# MK24F12 register map
Vendor: Freescale Semiconductor, Inc.; Series: Kinetis_K; File version: 1.6
CPU: CM4 r0p1, little endian, no MPU, FPU, VTOR, 4 interrupt priority bits
Registers are 32-bit, read-write, reset 0x0 unless marked. A register's access mark holds for its fields unless they carry their own. Offsets are from the block's base; [hi:lo] are bit positions; {n}, {i} and the like mark numbered series; 'fields as' and 'values as' point back to an identical list.

## AXBS — Crossbar switch
Base 0x40004000; register names take the prefix AXBS_
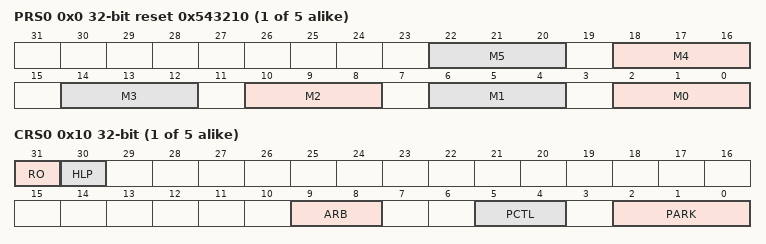
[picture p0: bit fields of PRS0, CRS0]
{0x0+0x100*i} PRS{i} (i=0..4) reset 0x543210 — Priority Registers Slave
  [all] fields
    0=This master has level 1, or highest, priority when accessing the slave port; {v}=This master has level {v+1} priority when accessing the slave port (v=1..6); 7=This master has level 8, or lowest, priority when accessing the slave port
  [4n+2:4n] M{n} (n=0..5) — Master {n} Priority. Sets the arbitration priority for this port on the associated slave port.
{0x10+0x100*i} CRS{i} (i=0..4) — Control Register
  [31] RO — Read Only
    0=The slave port's registers are writeable; 1=The slave port's registers are read-only and cannot be written. Attempted writes have no effect on the registers and result in a bus error response.
  [30] HLP — Halt Low Priority
    0=The low power mode request has the highest priority for arbitration on this slave port; 1=The low power mode request has the lowest initial priority for arbitration on this slave port
  [9:8] ARB — Arbitration Mode
    0=Fixed priority; 1=Round-robin, or rotating, priority
  [5:4] PCTL — Parking Control
    0=When no master makes a request, the arbiter parks the slave port on the master port defined by the PARK field; 1=When no master makes a request, the arbiter parks the slave port on the last master to be in control of the slave port; 2=When no master makes a request, the slave port is not parked on a master and the arbiter drives all outputs to a constant safe state
  [2:0] PARK
    {v}=Park on master port M{v} (v=0..7)
{0x800+0x100*i} MGPCR{i} (i=0..2) — Master General Purpose Control Register
  [2:0] AULB — Arbitrates On Undefined Length Bursts
    0=No arbitration is allowed during an undefined length burst; 1=Arbitration is allowed at any time during an undefined length burst; 2=Arbitration is allowed after four beats of an undefined length burst; 3=Arbitration is allowed after eight beats of an undefined length burst; 4=Arbitration is allowed after 16 beats of an undefined length burst
0xC00 MGPCR4 — Master General Purpose Control Register
  fields as MGPCR0
0xD00 MGPCR5 — Master General Purpose Control Register
  fields as MGPCR0

## FTFE — Flash Memory Interface
Base 0x40020000; register names take the prefix FTFE_
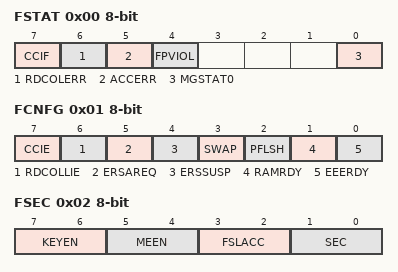
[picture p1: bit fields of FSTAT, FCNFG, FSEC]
0x00 FSTAT 8-bit — Flash Status Register
  [7] CCIF — Command Complete Interrupt Flag
    0=FTFE command in progress; 1=FTFE command has completed
  [6] RDCOLERR — FTFE Read Collision Error Flag
    0=No collision error detected; 1=Collision error detected
  [5] ACCERR — Flash Access Error Flag
    0=No access error detected; 1=Access error detected
  [4] FPVIOL — Flash Protection Violation Flag
    0=No protection violation detected; 1=Protection violation detected
  [0] MGSTAT0 ro — Memory Controller Command Completion Status Flag
0x01 FCNFG 8-bit — Flash Configuration Register
  [7] CCIE — Command Complete Interrupt Enable
    0=Command complete interrupt disabled; 1=Command complete interrupt enabled. An interrupt request is generated whenever the FSTAT[CCIF] flag is set.
  [6] RDCOLLIE — Read Collision Error Interrupt Enable
    0=Read collision error interrupt disabled; 1=Read collision error interrupt enabled. An interrupt request is generated whenever an FTFE read collision error is detected (see the description of FSTAT[RDCOLERR]).
  [5] ERSAREQ ro — Erase All Request
    0=No request or request complete; 1=Request to: run the Erase All Blocks command, verify the erased state, program the security byte in the Flash Configuration Field to the unsecure state, and release MCU security by setting the FSEC[SEC] field to the unsecure state
  [4] ERSSUSP — Erase Suspend
    0=No suspend requested; 1=Suspend the current Erase Flash Sector command execution
  [3] SWAP ro
    0=Program flash 0 block is located at relative address 0x0000; 1=For devices with FlexNVM: Reserved Program flash 1 block is located at relative address 0x0000
  [2] PFLSH ro — FTFE configuration
    1=FTFE configuration supports four program flash blocks
  [1] RAMRDY ro — RAM Ready
    0=Programming acceleration RAM is not available; 1=Programming acceleration RAM is available
  [0] EEERDY ro — During the reset sequence, the EEERDY flag remains clear while CCIF=0 and only sets if the FlexNVM block is partitioned for EEPROM
0x02 FSEC 8-bit ro reset not defined — Flash Security Register
  [7:6] KEYEN — Backdoor Key Security Enable
    0=Backdoor key access disabled; 1=Backdoor key access disabled (preferred KEYEN state to disable backdoor key access); 2=Backdoor key access enabled; 3=Backdoor key access disabled
  [5:4] MEEN — Mass Erase Enable Bits
    0=Mass erase is enabled; 1=Mass erase is enabled; 2=Mass erase is disabled; 3=Mass erase is enabled
  [3:2] FSLACC — Freescale Failure Analysis Access Code
    0=Freescale factory access granted; 1=Freescale factory access denied; 2=Freescale factory access denied; 3=Freescale factory access granted
  [1:0] SEC — Flash Security
    0=MCU security status is secure; 1=MCU security status is secure; 2=MCU security status is unsecure (The standard shipping condition of the FTFE is unsecure.); 3=MCU security status is secure
0x03 FOPT 8-bit ro reset not defined — Flash Option Register
  [7:0] OPT — Nonvolatile Option
0x04 FCCOB{x} (x=3,2,1,0,7,6,5,4,B,A,9,8; step 0x1) 8-bit — Flash Common Command Object Registers
  [7:0] CCOBn — The FCCOB register provides a command code and relevant parameters to the memory controller
0x10 FPROT{x} (x=3,2,1,0; step 0x1) 8-bit reset not defined — Program Flash Protection Registers
  [7:0] PROT — Program Flash Region Protect
    0=Program flash region is protected; 1=Program flash region is not protected

## Notices in the file
Redistribution and use in source and binary forms, with or without modification,
are permitted provided that the following conditions are met:
o Redistributions of source code must retain the above copyright notice, this list
of conditions and the following disclaimer.
o Redistributions in binary form must reproduce the above copyright notice, this
list of conditions and the following disclaimer in the documentation and/or
other materials provided with the distribution.
o Neither the name of Freescale Semiconductor, Inc. nor the names of its
contributors may be used to endorse or promote products derived from this
software without specific prior written permission.
THIS SOFTWARE IS PROVIDED BY THE COPYRIGHT HOLDERS AND CONTRIBUTORS "AS IS" AND
ANY EXPRESS OR IMPLIED WARRANTIES, INCLUDING, BUT NOT LIMITED TO, THE IMPLIED
WARRANTIES OF MERCHANTABILITY AND FITNESS FOR A PARTICULAR PURPOSE ARE
DISCLAIMED. IN NO EVENT SHALL THE COPYRIGHT HOLDER OR CONTRIBUTORS BE LIABLE FOR
ANY DIRECT, INDIRECT, INCIDENTAL, SPECIAL, EXEMPLARY, OR CONSEQUENTIAL DAMAGES
(INCLUDING, BUT NOT LIMITED TO, PROCUREMENT OF SUBSTITUTE GOODS OR SERVICES;
LOSS OF USE, DATA, OR PROFITS; OR BUSINESS INTERRUPTION) HOWEVER CAUSED AND ON
ANY THEORY OF LIABILITY, WHETHER IN CONTRACT, STRICT LIABILITY, OR TORT
(INCLUDING NEGLIGENCE OR OTHERWISE) ARISING IN ANY WAY OUT OF THE USE OF THIS
SOFTWARE, EVEN IF ADVISED OF THE POSSIBILITY OF SUCH DAMAGE.
